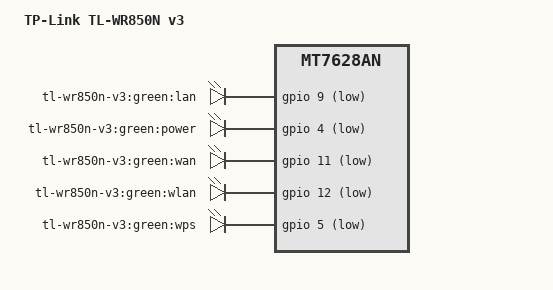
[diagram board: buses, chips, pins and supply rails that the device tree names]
#include "mt7628an_tplink_tl-wr850n-v3.dtsi"

/ {
	compatible = "tplink,tl-wr850n-v3", "mediatek,mt7628an-soc";
	model = "TP-Link TL-WR850N v3";

	aliases {
		led-boot = &led_power;
		led-failsafe = &led_power;
		led-running = &led_power;
		led-upgrade = &led_power;
	};

	leds {
		compatible = "gpio-leds";

		lan {
			label = "tl-wr850n-v3:green:lan";
			gpios = <&gpio 9 GPIO_ACTIVE_LOW>;
		};

		led_power: power {
			label = "tl-wr850n-v3:green:power";
			gpios = <&gpio 4 GPIO_ACTIVE_LOW>;
		};

		wan {
			label = "tl-wr850n-v3:green:wan";
			gpios = <&gpio 11 GPIO_ACTIVE_LOW>;
		};

		wlan {
			label = "tl-wr850n-v3:green:wlan";
			gpios = <&gpio 12 GPIO_ACTIVE_LOW>;
		};

		wps {
			label = "tl-wr850n-v3:green:wps";
			gpios = <&gpio 5 GPIO_ACTIVE_LOW>;
		};
	};
};

&ralinkgpio {
	ralink,group = "p0led_an", "p2led_an", "perst", "wdt";
};
